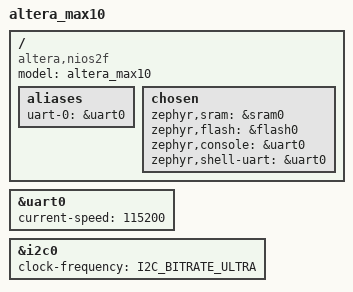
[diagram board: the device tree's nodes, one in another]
/* SPDX-License-Identifier: Apache-2.0 */

/dts-v1/;

#include <nios2f.dtsi>

/ {
	model = "altera_max10";
	compatible = "altera,nios2f";

	aliases {
		uart-0 = &uart0;
	};

	chosen {
		zephyr,sram = &sram0;
		zephyr,flash = &flash0;
		zephyr,console = &uart0;
		zephyr,shell-uart = &uart0;
	};
};

&uart0 {
	status = "okay";
	current-speed = <115200>;
};

&i2c0 {
	status = "okay";
	clock-frequency = <I2C_BITRATE_ULTRA>;
};
